# IMC300A register map
Vendor: Infineon; File version: 1.0.0
CPU: CM0 r0p0, little endian, no MPU, no FPU, 2 interrupt priority bits
Registers are 32-bit, read-write, reset 0x0 unless marked. A register's access mark holds for its fields unless they carry their own. Offsets are from the block's base; [hi:lo] are bit positions; {n}, {i} and the like mark numbered series.

## SCU_POWER — System Control Unit
Base 0x40010200
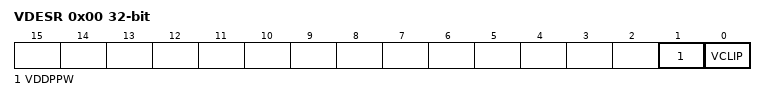
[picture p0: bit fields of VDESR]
0x00 VDESR ro — Voltage Detector Status Register
  [1] VDDPPW — VDDPPW Indication
    0=VDDP is above pre-warning threshold; 1=VDDP is below pre-warningthreshold
  [0] VCLIP — VCLIP Indication
    0=VCLIP is not active; 1=VCLIP is active

## SCU_RESET — System Control Unit
Base 0x40010400
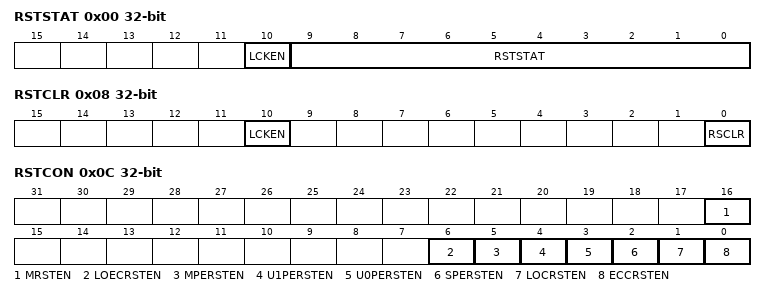
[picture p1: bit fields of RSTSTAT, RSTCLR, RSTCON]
0x00 RSTSTAT ro (reset mask 0xFFFFF000) — RCU Reset Status
  [10] LCKEN — Enable Lockup Status
    0=Reset by Lockup disabled; 1=Reset by Lockup enabled
  [9:0] RSTSTAT — Reset Status Information
0x04 RSTSET wo — RCU Reset Set Register
  [10] LCKEN — Enable Lockup Reset
    0=set no effect; 1=Enable reset when Lockup gets asserted
0x08 RSTCLR wo — RCU Reset Clear Register
  [10] LCKEN — Enable Lockup Reset
    0=Clear no effect; 1=Disable reset when Lockup gets asserted
  [0] RSCLR — Clear Reset Status
    0=Clear no effect; 1=Clears field RSTSTAT.RSTSTAT
0x0C RSTCON access per field — RCU Reset Control Register
  [16] MRSTEN wo — Enable Master Reset
    0=No Master reset; 1=Triggered Master reset
  [6] LOECRSTEN rw — Enable Loss of External Clock Reset
    0=No reset when loss of external clock occur; 1=Reset when loss of external clock occur
  [5] MPERSTEN rw — Enable MultiCAN+SRAM Parity Error Reset
    0=No reset when MultiCAN+ memory parity error occur; 1=Reset when MultiCAN+ memory parity error occur
  [4] U1PERSTEN rw — Enable USIC01 SRAM Parity Error Reset
    0=No reset when USIC1 memory parity error occur; 1=Reset when USIC1 memory parity error occur
  [3] U0PERSTEN rw — Enable USIC0 SRAM Parity Error Reset
    0=No reset when USIC0 memory parity error occur; 1=Reset when USIC0 memory parity error occur
  [2] SPERSTEN rw — Enable 16kbytes SRAM Parity Error Reset
    0=No reset when SRAM parity error occur; 1=Reset when SRAM parity error occur
  [1] LOCRSTEN rw — Enable Loss of DCO1 Clock Reset
    0=No reset when loss of DCO1 clock occur; 1=Reset when loss of DCO1 clock occur
  [0] ECCRSTEN rw — Enable ECC Error Reset
    0=No reset when ECC double bit error occur; 1=Reset when ECC double bit error occur

## COMPARATOR — System Control Unit
Base 0x40010500
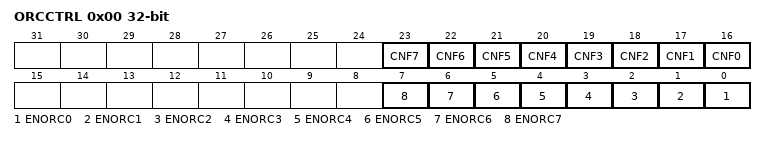
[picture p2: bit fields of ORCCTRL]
0x00 ORCCTRL — Out Of Range Comparator Control Register
  [n+16] CNF{n} (n=0..7) — Out of Range Comparator Flag {n}
    0=Falling edge trigger out of range event flag {n}; 1=Rising edge trigger out of range event flag {n}
  [n] ENORC{n} (n=0..7) — Enable Out of Range Comparator {n}
    0=Out of range comparator {n} disabled; 1=Out of range comparator {n} enabled

## SCU_ANALOG — System Control Unit
Base 0x40011000
0x24 ANATSECTRL 16-bit — Temperature Sensor Control Register
  [0] TSE_EN — Temperature sensor enable
    0=Temperature sensor is disabled; 1=Temperature sensor is switched on
0x30 ANATSEIH 16-bit — Temperature Sensor High Temperature Interrupt Register
  [15:0] TSE_IH — Counter value for high temperature interrupt
0x34 ANATSEIL 16-bit reset 0xFFFF — Temperature Sensor Low Temperature Interrupt Register
  [15:0] TSE_IL — Counter value for low temperature interrupt
0x40 ANATSEMON 16-bit ro — Temperature Sensor Counter2 Monitor Register
  [15:0] TSE_MON — Result values; loaded by TSE_DONE
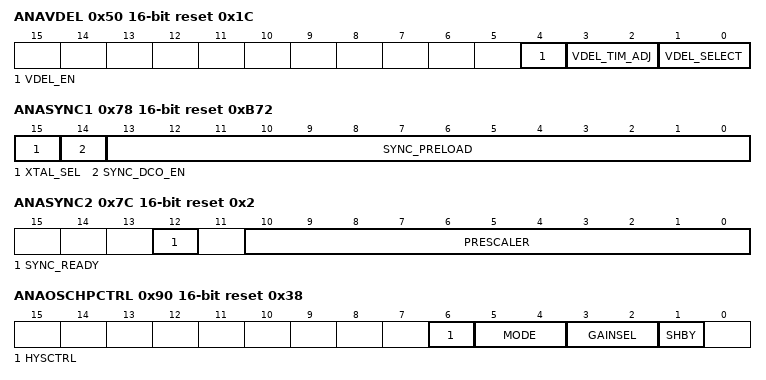
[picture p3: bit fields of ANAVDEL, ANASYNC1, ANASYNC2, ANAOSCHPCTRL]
0x50 ANAVDEL 16-bit reset 0x1C — Voltage Detector Control Register
  [4] VDEL_EN — VDEL unit Enable
    0=VDEL is disabled; 1=VDEL is active
  [3:2] VDEL_TIM_ADJ — VDEL Timing Setting
    0=typ 1us - slowest response time; 1=typ 500n; 2=typ 250n; 3=no delay - fastest response time
  [1:0] VDEL_SELECT — VDEL Range Select
    0=2.25V; 1=3.0V; 2=4.4V
0x6C ANAOFFSET 16-bit reset 0x40 — DCO1 Offset Register
  [6:0] ADJL_OFFSET
    0=minus 3 percent, typ; 63=DCO1 ADJL value is reduced by 1 step (DCO_ADJL - 1); 64=0, DCO_ADJL is not changed, default; 65=DCO1 ADJL value is increased by 1 step (DCO_ADJL + 1); 127=plus 3 percent, typ
0x78 ANASYNC1 16-bit reset 0xB72 — DCO1 Sync Control Register 1
  [15] XTAL_SEL — Oscillator Source select
    0=OSC_LP is selected; 1=OSC_HP is selected
  [14] SYNC_DCO_EN — DCO1 synchronization feature enable
    0=Disable DCO1 synchronization; 1=Enable DCO1 synchronization via external clock source
  [13:0] SYNC_PRELOAD — Counter target value, which defines the update cycle
    0x1FFF=Longest integration time = best accuracy
0x7C ANASYNC2 16-bit access per field reset 0x2 — DCO1 Sync Control Register 2
  [12] SYNC_READY ro — DCO1 frequency reached its target value
    0=Actual DCO1 frequency is out of targe; 1=DCO1 is synchronized to the XTAL frequency
  [10:0] PRESCALER rw — Prescaler value
    0=Bypass: Internal sync counter frequency = crystal frequency; 1=DIV1: Internal sync counter feed freq. = crystal frequency/1; 2=DIV2: Internal sync counter feed freq. = crystal frequency/2; 0x7FF=Maximum divider value (for best accuracy, but slowest response)
0x8C ANAOSCLPCTRL 16-bit reset 0x3 — OSC_LP Control Register
  [1:0] MODE — OSC_LP Oscillator Mode
    0=Oscillator is enabled and in operation mode (OSC mode); 1=Oscillator is enabled, shaper is bypassed; 2=Oscillator is in power down mode; 3=Oscillator is in power down mode , Pad can be used in GPIO mode
0x90 ANAOSCHPCTRL 16-bit reset 0x38 — OSC_HP Control Register
  [6] HYSCTRL — Shaper Hystersis Mode
    0=External clock frequency below 20MHz; 1=External clock frequency above 20MHz
  [5:4] MODE — OSC_HP Oscillator Mode
    0=Oscillator Mode with shaper enabled; 1=External Clock Input Mode with shaper enabled; 2=Oscillator Mode with shaper disabled; 3=Oscillator is in power down mode with shaper disabled
  [3:2] GAINSEL — OSC_HP Oscillator Gain Selection
    0=Gain control is configured for frequencies from 4 MHz to y1 MHz; 1=Gain control is configured for frequencies from 4 MHz to y2 MHz; 2=Gain control is configured for frequencies from 4 MHz to 20 MHz
  [1] SHBY — Shaper Bypass Mode
    0=The shaper is not bypassed; 1=The shaper is bypassed

## Notices in the file
Copyright (C) 2017 Infineon Technologies AG. All rights reserved.
Infineon Technologies AG (Infineon) is supplying this software for use with
Infineon's microcontrollers.  This file can be freely distributed within
development tools that are supporting such microcontrollers.
THIS SOFTWARE IS PROVIDED "AS IS".  NO WARRANTIES, WHETHER EXPRESS, IMPLIED
OR STATUTORY, INCLUDING, BUT NOT LIMITED TO, IMPLIED WARRANTIES OF
MERCHANTABILITY AND FITNESS FOR A PARTICULAR PURPOSE APPLY TO THIS SOFTWARE.
INFINEON SHALL NOT, IN ANY CIRCUMSTANCES, BE LIABLE FOR SPECIAL, INCIDENTAL,
OR CONSEQUENTIAL DAMAGES, FOR ANY REASON WHATSOEVER.
